# TESTMCU register map
File version: 1.0
Minimal fixture for SVD tests
Registers are 32-bit, access not given, no defined reset value unless marked. A register's access mark holds for its fields unless they carry their own. Offsets are from the block's base; lines under a group give offsets from that group; [hi:lo] are bit positions; {n}, {i} and the like mark numbered series; 'fields as' and 'values as' point back to an identical list; <NAME> marks a mode.

## Memory map
0x40020000 GPIOA

## GPIOA
Base 0x40020000
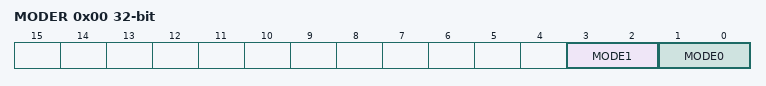
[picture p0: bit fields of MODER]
0x00 MODER
  [3:2] MODE1
  [1:0] MODE0
    0=Input; 1=Output
0x18 BSRR
